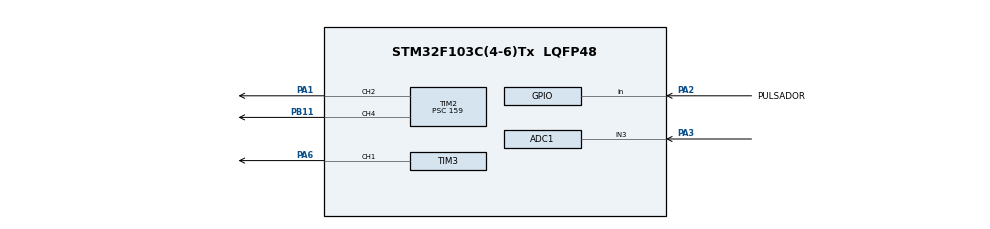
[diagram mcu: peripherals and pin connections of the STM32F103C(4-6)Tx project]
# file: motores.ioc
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ADC1.Channel-0\#ChannelRegularConversion=ADC_CHANNEL_3
ADC1.ContinuousConvMode=ENABLE
ADC1.NbrOfConversion=1
ADC1.NbrOfConversionFlag=1
ADC1.Rank-0\#ChannelRegularConversion=1
ADC1.SamplingTime-0\#ChannelRegularConversion=ADC_SAMPLETIME_71CYCLES_5
ADC1.master=1
Mcu.Family=STM32F1
Mcu.Name=STM32F103C(4-6)Tx
Mcu.Package=LQFP48
NVIC.PriorityGroup=NVIC_PRIORITYGROUP_4
PA1.Signal=S_TIM2_CH2
PA2.GPIO_Label=PULSADOR
PA2.GPIO_PuPd=GPIO_PULLDOWN
PA2.Signal=GPIO_Input
PA3.Signal=ADCx_IN3
PA6.Signal=S_TIM3_CH1
PB11.Signal=S_TIM2_CH4
ProjectManager.HeapSize=0x200
ProjectManager.StackSize=0x400
ProjectManager.TargetToolchain=STM32CubeIDE
RCC.APB1Freq_Value=8000000
RCC.APB2Freq_Value=8000000
SH.ADCx_IN3.0=ADC1_IN3,IN3
SH.S_TIM2_CH2.0=TIM2_CH2,PWM Generation2 CH2
SH.S_TIM2_CH4.0=TIM2_CH4,PWM Generation4 CH4
SH.S_TIM3_CH1.0=TIM3_CH1,PWM Generation1 CH1
TIM2.Channel-PWM\ Generation2\ CH2=TIM_CHANNEL_2
TIM2.Channel-PWM\ Generation4\ CH4=TIM_CHANNEL_4
TIM2.OCMode_PWM-PWM\ Generation2\ CH2=TIM_OCMODE_PWM2
TIM2.Period=999
TIM2.Prescaler=159
TIM3.Channel-PWM\ Generation1\ CH1=TIM_CHANNEL_1
TIM3.OCMode_PWM-PWM\ Generation1\ CH1=TIM_OCMODE_PWM2
TIM3.Period=999
TIM3.Prescaler=159
VP_SYS_VS_ND.Mode=No_Debug
VP_TIM2_VS_ClockSourceINT.Mode=Internal
VP_TIM3_VS_ClockSourceINT.Mode=Internal
board=custom

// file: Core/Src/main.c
/* USER CODE BEGIN Header */
/**
  ******************************************************************************
  * @file           : main.c
  * @brief          : Main program body
  ******************************************************************************
  * @attention
  *
  * Copyright (c) 2024 STMicroelectronics.
  * All rights reserved.
  *
  * This software is licensed under terms that can be found in the LICENSE file
  * in the root directory of this software component.
  * If no LICENSE file comes with this software, it is provided AS-IS.
  *
  ******************************************************************************
  */
/* USER CODE END Header */
#include "main.h"

ADC_HandleTypeDef hadc1;

TIM_HandleTypeDef htim2;
TIM_HandleTypeDef htim3;

void SystemClock_Config(void);
static void MX_GPIO_Init(void);
static void MX_TIM2_Init(void);
static void MX_ADC1_Init(void);
static void MX_TIM3_Init(void);
long map(long x, long in_min, long in_max, long out_min, long out_max);

int main(void)
{

  /* MCU Configuration--------------------------------------------------------*/

  /* Reset of all peripherals, Initializes the Flash interface and the Systick. */
  HAL_Init();

  /* Configure the system clock */
  SystemClock_Config();

  /* Initialize all configured peripherals */
  MX_GPIO_Init();
  MX_TIM2_Init();
  MX_ADC1_Init();
  MX_TIM3_Init();
  /* USER CODE BEGIN 2 */
  HAL_TIM_PWM_Start(&htim2, TIM_CHANNEL_2); // Inicia el PWM 2
  TIM2->CCR2=100;
  HAL_ADC_Start(&hadc1); // Inicia la conversión ADC
  HAL_TIM_PWM_Start(&htim3, TIM_CHANNEL_1); // Inicia el PWM 3

  /* USER CODE END 2 */

  /* Infinite loop */
  /* USER CODE BEGIN WHILE */
  while (1)
  {
	  // CONTROL SERVO
	  	 // TIM2->CCR2=50;  ---> -90°
	  	 // TIM2->CCR2=75;  --->  0°
	  	 // TIM2->CCR2=100; --->  90°
	    if (HAL_GPIO_ReadPin(PULSADOR_GPIO_Port, PULSADOR_Pin) == GPIO_PIN_RESET) // Si el pulsador está en bajo
	    {
	        TIM2->CCR2=75;  // 0°
	    }
	    else // Si el pulsador está en alto
	    {
	        TIM2->CCR2=100; // 90°
	    }

	  // CONVERSIÓN A/D
	      uint32_t adcValue = HAL_ADC_GetValue(&hadc1);// Obtiene el valor de la conversión ADC

	      // Mapea el valor del ADC (0 - 4095) al rango del ciclo de trabajo del PWM (0 - 159)
	      //uint32_t pwmDutyCycle = map(adcValue, 0, 4095, 0, htim3.Init.Period);
	      //Mapeo para control del motor
	      uint32_t pwmDutyCycle = map(adcValue, 0, 4095, 50, 100);

	      // Ajusta el ciclo de trabajo del PWM
	      TIM3->CCR1=pwmDutyCycle;

	      // Espera un poco antes de la próxima lectura
	      HAL_Delay(2000);

    /* USER CODE END WHILE */

  }
}

void SystemClock_Config(void)
{
  RCC_OscInitTypeDef RCC_OscInitStruct = {0};
  RCC_ClkInitTypeDef RCC_ClkInitStruct = {0};
  RCC_PeriphCLKInitTypeDef PeriphClkInit = {0};

  /** Initializes the RCC Oscillators according to the specified parameters
  * in the RCC_OscInitTypeDef structure.
  */
  RCC_OscInitStruct.OscillatorType = RCC_OSCILLATORTYPE_HSI;
  RCC_OscInitStruct.HSIState = RCC_HSI_ON;
  RCC_OscInitStruct.HSICalibrationValue = RCC_HSICALIBRATION_DEFAULT;
  RCC_OscInitStruct.PLL.PLLState = RCC_PLL_NONE;
  if (HAL_RCC_OscConfig(&RCC_OscInitStruct) != HAL_OK)
  {
    Error_Handler();
  }

  /** Initializes the CPU, AHB and APB buses clocks
  */
  RCC_ClkInitStruct.ClockType = RCC_CLOCKTYPE_HCLK|RCC_CLOCKTYPE_SYSCLK
                              |RCC_CLOCKTYPE_PCLK1|RCC_CLOCKTYPE_PCLK2;
  RCC_ClkInitStruct.SYSCLKSource = RCC_SYSCLKSOURCE_HSI;
  RCC_ClkInitStruct.AHBCLKDivider = RCC_SYSCLK_DIV1;
  RCC_ClkInitStruct.APB1CLKDivider = RCC_HCLK_DIV1;
  RCC_ClkInitStruct.APB2CLKDivider = RCC_HCLK_DIV1;

  if (HAL_RCC_ClockConfig(&RCC_ClkInitStruct, FLASH_LATENCY_0) != HAL_OK)
  {
    Error_Handler();
  }
  PeriphClkInit.PeriphClockSelection = RCC_PERIPHCLK_ADC;
  PeriphClkInit.AdcClockSelection = RCC_ADCPCLK2_DIV2;
  if (HAL_RCCEx_PeriphCLKConfig(&PeriphClkInit) != HAL_OK)
  {
    Error_Handler();
  }
}

static void MX_ADC1_Init(void)
{

  ADC_ChannelConfTypeDef sConfig = {0};

  /** Common config
  */
  hadc1.Instance = ADC1;
  hadc1.Init.ScanConvMode = ADC_SCAN_DISABLE;
  hadc1.Init.ContinuousConvMode = ENABLE;
  hadc1.Init.DiscontinuousConvMode = DISABLE;
  hadc1.Init.ExternalTrigConv = ADC_SOFTWARE_START;
  hadc1.Init.DataAlign = ADC_DATAALIGN_RIGHT;
  hadc1.Init.NbrOfConversion = 1;
  if (HAL_ADC_Init(&hadc1) != HAL_OK)
  {
    Error_Handler();
  }

  /** Configure Regular Channel
  */
  sConfig.Channel = ADC_CHANNEL_3;
  sConfig.Rank = ADC_REGULAR_RANK_1;
  sConfig.SamplingTime = ADC_SAMPLETIME_71CYCLES_5;
  if (HAL_ADC_ConfigChannel(&hadc1, &sConfig) != HAL_OK)
  {
    Error_Handler();
  }

}

static void MX_TIM2_Init(void)
{

  TIM_ClockConfigTypeDef sClockSourceConfig = {0};
  TIM_MasterConfigTypeDef sMasterConfig = {0};
  TIM_OC_InitTypeDef sConfigOC = {0};

  htim2.Instance = TIM2;
  htim2.Init.Prescaler = 159;
  htim2.Init.CounterMode = TIM_COUNTERMODE_UP;
  htim2.Init.Period = 999;
  htim2.Init.ClockDivision = TIM_CLOCKDIVISION_DIV1;
  htim2.Init.AutoReloadPreload = TIM_AUTORELOAD_PRELOAD_DISABLE;
  if (HAL_TIM_Base_Init(&htim2) != HAL_OK)
  {
    Error_Handler();
  }
  sClockSourceConfig.ClockSource = TIM_CLOCKSOURCE_INTERNAL;
  if (HAL_TIM_ConfigClockSource(&htim2, &sClockSourceConfig) != HAL_OK)
  {
    Error_Handler();
  }
  if (HAL_TIM_PWM_Init(&htim2) != HAL_OK)
  {
    Error_Handler();
  }
  sMasterConfig.MasterOutputTrigger = TIM_TRGO_RESET;
  sMasterConfig.MasterSlaveMode = TIM_MASTERSLAVEMODE_DISABLE;
  if (HAL_TIMEx_MasterConfigSynchronization(&htim2, &sMasterConfig) != HAL_OK)
  {
    Error_Handler();
  }
  sConfigOC.OCMode = TIM_OCMODE_PWM2;
  sConfigOC.Pulse = 0;
  sConfigOC.OCPolarity = TIM_OCPOLARITY_HIGH;
  sConfigOC.OCFastMode = TIM_OCFAST_DISABLE;
  if (HAL_TIM_PWM_ConfigChannel(&htim2, &sConfigOC, TIM_CHANNEL_2) != HAL_OK)
  {
    Error_Handler();
  }
  sConfigOC.OCMode = TIM_OCMODE_PWM1;
  if (HAL_TIM_PWM_ConfigChannel(&htim2, &sConfigOC, TIM_CHANNEL_4) != HAL_OK)
  {
    Error_Handler();
  }
  HAL_TIM_MspPostInit(&htim2);

}

static void MX_TIM3_Init(void)
{

  TIM_ClockConfigTypeDef sClockSourceConfig = {0};
  TIM_MasterConfigTypeDef sMasterConfig = {0};
  TIM_OC_InitTypeDef sConfigOC = {0};

  htim3.Instance = TIM3;
  htim3.Init.Prescaler = 159;
  htim3.Init.CounterMode = TIM_COUNTERMODE_UP;
  htim3.Init.Period = 999;
  htim3.Init.ClockDivision = TIM_CLOCKDIVISION_DIV1;
  htim3.Init.AutoReloadPreload = TIM_AUTORELOAD_PRELOAD_DISABLE;
  if (HAL_TIM_Base_Init(&htim3) != HAL_OK)
  {
    Error_Handler();
  }
  sClockSourceConfig.ClockSource = TIM_CLOCKSOURCE_INTERNAL;
  if (HAL_TIM_ConfigClockSource(&htim3, &sClockSourceConfig) != HAL_OK)
  {
    Error_Handler();
  }
  if (HAL_TIM_PWM_Init(&htim3) != HAL_OK)
  {
    Error_Handler();
  }
  sMasterConfig.MasterOutputTrigger = TIM_TRGO_RESET;
  sMasterConfig.MasterSlaveMode = TIM_MASTERSLAVEMODE_DISABLE;
  if (HAL_TIMEx_MasterConfigSynchronization(&htim3, &sMasterConfig) != HAL_OK)
  {
    Error_Handler();
  }
  sConfigOC.OCMode = TIM_OCMODE_PWM2;
  sConfigOC.Pulse = 0;
  sConfigOC.OCPolarity = TIM_OCPOLARITY_HIGH;
  sConfigOC.OCFastMode = TIM_OCFAST_DISABLE;
  if (HAL_TIM_PWM_ConfigChannel(&htim3, &sConfigOC, TIM_CHANNEL_1) != HAL_OK)
  {
    Error_Handler();
  }
  HAL_TIM_MspPostInit(&htim3);

}

static void MX_GPIO_Init(void)
{
  GPIO_InitTypeDef GPIO_InitStruct = {0};

  /* GPIO Ports Clock Enable */
  __HAL_RCC_GPIOA_CLK_ENABLE();
  __HAL_RCC_GPIOB_CLK_ENABLE();

  /*Configure GPIO pin : PULSADOR_Pin */
  GPIO_InitStruct.Pin = PULSADOR_Pin;
  GPIO_InitStruct.Mode = GPIO_MODE_INPUT;
  GPIO_InitStruct.Pull = GPIO_PULLDOWN;
  HAL_GPIO_Init(PULSADOR_GPIO_Port, &GPIO_InitStruct);

}

/* USER CODE BEGIN 4 */
long map(long x, long in_min, long in_max, long out_min, long out_max) {
  return (x - in_min) * (out_max - out_min) / (in_max - in_min) + out_min;
}

/* USER CODE END 4 */

void Error_Handler(void)
{
  __disable_irq();
  while (1)
  {
  }
}
